# tviic2d6m register map
Vendor: Infineon Technologies; Series: TVIIC2D6M; File version: 1.0
CPU: CM7 r0p1, little endian, MPU, FPU, double-precision FPU, I-cache, D-cache, VTOR, ITCM, DTCM, 3 interrupt priority bits, 16 interrupts
Registers are 32-bit, read-write, reset 0x0 unless marked. A register's access mark holds for its fields unless they carry their own. Offsets are from the block's base; [hi:lo] are bit positions; lines under a group give offsets from that group; {n}, {i} and the like mark numbered series.

## PROT — Protection
Base 0x40230000
0x00 SMPU group
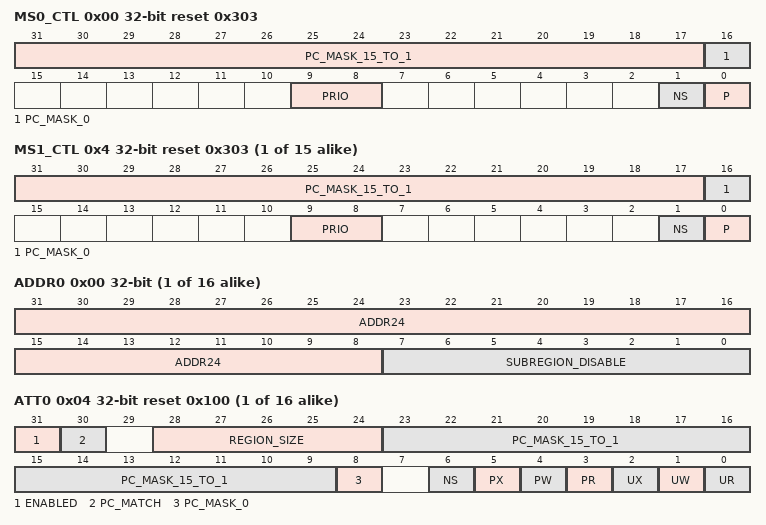
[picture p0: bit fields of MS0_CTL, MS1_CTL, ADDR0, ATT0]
  0x00 MS0_CTL reset 0x303 — Master 0 protection context control
    [31:17] PC_MASK_15_TO_1 — Protection context mask for protection contexts '15' down to '1'. Bit PC_MASK_15_TO_1[i] indicates if the MPU MS_CTL.PC[3:0] protection context field can be set to the value 'i+1': - PC_MASK_15_TO_1[i] is '0': MPU MS_CTL.PC[3:0] can NOT be set to 'i+1'; and PC[3:0] is not changed. If the protection context of the write transfer is '0', protection is not applied and PC[3:0] can be changed. - PC_MASK_15_TO_1[i] is '1': MPU MS_CTL.PC[3:0] can be set to 'i+1'. Note: When CPUSS_CM0_PC_CTL.VALID[i] is '1' (the associated protection context handler is valid), write transfers to PC_MASK_15_TO_1[i-1] always write '0', regardless of data written. This ensures that when valid protection context handlers are used to enter protection contexts 1, 2 or 3 through (HW modifies MPU MS_CTL.PC[3:0] on entry of the handler), it is NOT possible for SW to enter those protection contexts (SW modifies MPU MS_CTL.PC[3:0]).
    [16] PC_MASK_0 ro — Protection context mask for protection context '0'. This field is a constant '0': - PC_MASK_0 is '0': MPU MS_CTL.PC[3:0] can NOT be set to '0' and PC[3:0] is not changed. If the protection context of the write transfer is '0', protection is not applied and PC[3:0] can be changed.
    [9:8] PRIO — Device wide bus arbitration priority setting ('0': highest priority, '3': lowest priority). Notes: The AHB-Lite interconnect performs arbitration on the individual beats/transfers of a burst (this optimizes latency over locality/bandwidth). The AXI-Lite interconnects performs a single arbitration for the complete burst (this optimizes locality/bandwidth over latency). Masters with the same priority setting form a 'priority group'. Within a 'priority group', round robin arbitration is performed.
    [1] NS — Security setting ('0': secure mode; '1': non-secure mode). Notes: This field is ONLY used for masters that do NOT provide their own secure/non-secure access control attribute. Note that the default/reset field value provides non-secure mode access capabilities to all masters.
    [0] P — Privileged setting ('0': user mode; '1': privileged mode). Notes: This field is ONLY used for masters that do NOT provide their own user/privileged access control attribute. The default/reset field value provides privileged mode access capabilities.
  {0x0+4j} MS{j}_CTL reset 0x303 (j=1..15) — Master {j} protection context control
    [31:17] PC_MASK_15_TO_1 — See MS0_CTL.PC_MASK_15_TO_1.
    [16] PC_MASK_0 ro — See MS0_CTL.PC_MASK_0.
    [9:8] PRIO — See MS0_CTL.PRIO
    [1] NS — See MS0_CTL.NS.
    [0] P — See MS0_CTL.P.
  {0x2000+0x40*j} SMPU_STRUCT[{j}] (j=0..15) group — SMPU structure
    0x00 ADDR0 reset not defined — SMPU region address 0 (slave structure)
      [31:8] ADDR24 — This field specifies the most significant bits of the 32-bit address of an address region. The region size is defined by ATT0.REGION_SIZE. A region of n Byte is always n Byte aligned. As a result, some of the lesser significant address bits of ADDR24 may be ignored in determining whether a bus transfer address is within an address region. E.g., a 64 KByte address region (REGION_SIZE is '15') is 64 KByte aligned, and ADDR24[7:0] are ignored.
      [7:0] SUBREGION_DISABLE — This field is used to individually disabled the eight equally sized subregions in which a region is partitioned. Subregion disable: Bit 0: subregion 0 disable. Bit 1: subregion 1 disable. Bit 2: subregion 2 disable. Bit 3: subregion 3 disable. Bit 4: subregion 4 disable. Bit 5: subregion 5 disable. Bit 6: subregion 6 disable. Bit 7: subregion 7 disable. E.g., a 64 KByte address region (ATT0.REGION_SIZE is '15') has eight 8 KByte subregions. The access control as defined by ATT0 applies if the bus transfer address is within the address region AND the addressed subregion is NOT disabled. Note that the smallest region size is 256 B and the smallest subregion size is 32 B.
    0x04 ATT0 reset 0x100 (reset mask 0x80000100) — SMPU region attributes 0 (slave structure)
      [31] ENABLED — Region enable: '0': Disabled. A disabled region will never result in a match on the bus transfer address. '1': Enabled. Note: a disabled address region performs logic gating to reduce dynamic power consumption.
      [30] PC_MATCH — This field specifies if the PC field participates in the 'matching' process or the 'access evaluation' process: '0': PC field participates in 'access evaluation'. '1': PC field participates in 'matching'. 'Matching' process. For each protection structure, the process identifies if a transfer address is contained within the address range. This identifies the 'matching' regions. 'Access evaluation' process. For each protection structure, the process evaluates the bus transfer access attributes against the access control attributes. Note that it is possible to define different access control for multiple protection contexts by using multiple protection structures with the same address region and PC_MATCH set to '1'.
      [28:24] REGION_SIZE — This field specifies the region size: '0'-'6': Undefined. '7': 256 B region '8': 512 B region '9': 1 KB region '10': 2 KB region '11': 4 KB region '12': 8 KB region '13': 16 KB region '14': 32 KB region '15': 64 KB region '16': 128 KB region '17': 256 KB region '18': 512 KB region '19': 1 MB region '20': 2 MB region '21': 4 MB region '22': 8 MB region '23': 16 MB region '24': 32 MB region '25': 64 MB region '26': 128 MB region '27': 256 MB region '28': 512 MB region '39': 1 GB region '30': 2 GB region '31': 4 GB region
      [23:9] PC_MASK_15_TO_1 — This field specifies protection context identifier based access control. Bit i: protection context i+1 enable. If '0', protection context i+1 access is disabled; i.e. not allowed. If '1', protection context i+1 access is enabled; i.e. allowed.
      [8] PC_MASK_0 ro — This field specifies protection context identifier based access control for protection context '0'.
      [6] NS — Non-secure: '0': Secure (secure accesses allowed, non-secure access NOT allowed). '1': Non-secure (both secure and non-secure accesses allowed).
      [5] PX — Privileged execute enable: '0': Disabled (privileged, execute accesses are NOT allowed). '1': Enabled (privileged, execute accesses are allowed).
      [4] PW — Privileged write enable: '0': Disabled (privileged, write accesses are NOT allowed). '1': Enabled (privileged, write accesses are allowed).
      [3] PR — Privileged read enable: '0': Disabled (privileged, read accesses are NOT allowed). '1': Enabled (privileged, read accesses are allowed).
      [2] UX — User execute enable: '0': Disabled (user, execute accesses are NOT allowed). '1': Enabled (user, execute accesses are allowed).
      [1] UW — User write enable: '0': Disabled (user, write accesses are NOT allowed). '1': Enabled (user, write accesses are allowed).
      [0] UR — User read enable: '0': Disabled (user, read accesses are NOT allowed). '1': Enabled (user, read accesses are allowed).
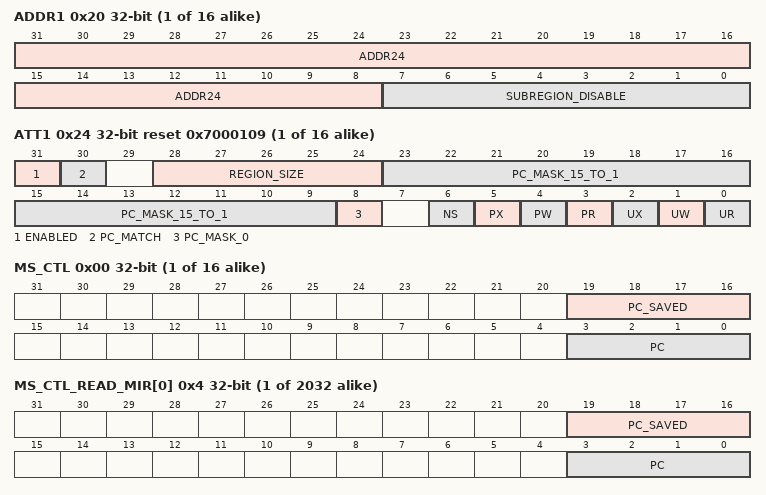
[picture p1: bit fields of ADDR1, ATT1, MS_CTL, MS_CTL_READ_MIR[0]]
    0x20 ADDR1 ro — SMPU region address 1 (master structure)
      [31:8] ADDR24 — This field specifies the most significant bits of the 32-bit address of an address region. 'ADDR_DEF1': base address of structure. Note: this field is read-only.
      [7:0] SUBREGION_DISABLE — This field is used to individually disabled the eight equally sized subregions in which a region is partitioned. Subregion disable: Bit 0: subregion 0 disable. Bit 1: subregion 1 disable. Bit 2: subregion 2 disable. Bit 3: subregion 3 disable. Bit 4: subregion 4 disable. Bit 5: subregion 5 disable. Bit 6: subregion 6 disable. Bit 7: subregion 7 disable. Two out of a total of eight 32 B subregions are enabled. These subregions includes region structures 0 and 1. Note: this field is read-only.
    0x24 ATT1 reset 0x7000109 (reset mask 0x9F00012D) — SMPU region attributes 1 (master structure)
      [31] ENABLED — Region enable: '0': Disabled. A disabled region will never result in a match on the bus transfer address. '1': Enabled.
      [30] PC_MATCH — This field specifies if the PC field participates in the 'matching' process or the 'access evaluation' process: '0': PC field participates in 'access evaluation'. '1': PC field participates in 'matching'. 'Matching' process. For each protection structure, the process identifies if a transfer address is contained within the address range. This identifies the 'matching' regions. 'Access evaluation' process. For each protection structure, the process evaluates the bus transfer access attributes against the access control attributes. Note that it is possible to define different access control for multiple protection contexts by using multiple protection structures with the same address region and PC_MATCH set to '1'.
      [28:24] REGION_SIZE ro — This field specifies the region size: '7': 256 B region (8 32 B subregions) Note: this field is read-only.
      [23:9] PC_MASK_15_TO_1 — This field specifies protection context identifier based access control. Bit i: protection context i+1 enable. If '0', protection context i+1 access is disabled; i.e. not allowed. If '1', protection context i+1 access is enabled; i.e. allowed.
      [8] PC_MASK_0 ro — This field specifies protection context identifier based access control for protection context '0'.
      [6] NS — Non-secure: '0': Secure (secure accesses allowed, non-secure access NOT allowed). '1': Non-secure (both secure and non-secure accesses allowed).
      [5] PX ro — Privileged execute enable: '0': Disabled (privileged, execute accesses are NOT allowed). '1': Enabled (privileged, execute accesses are allowed). Note that this register is constant '0'; i.e. privileged execute accesses are NEVER allowed.
      [4] PW — Privileged write enable: '0': Disabled (privileged, write accesses are NOT allowed). '1': Enabled (privileged, write accesses are allowed).
      [3] PR ro — Privileged read enable: '0': Disabled (privileged, read accesses are NOT allowed). '1': Enabled (privileged, read accesses are allowed). Note that this register is constant '1'; i.e. privileged read accesses are ALWAYS allowed.
      [2] UX ro — User execute enable: '0': Disabled (user, execute accesses are NOT allowed). '1': Enabled (user, execute accesses are allowed). Note that this register is constant '0'; i.e. user execute accesses are NEVER allowed.
      [1] UW — User write enable: '0': Disabled (user, write accesses are NOT allowed). '1': Enabled (user, write accesses are allowed).
      [0] UR ro — User read enable: '0': Disabled (user, read accesses are NOT allowed). '1': Enabled (user, read accesses are allowed). Note that this register is constant '1'; i.e. user read accesses are ALWAYS allowed.
{0x4000+0x400*i} MPU[{i}] (i=0..15) group
  0x00 MS_CTL — Master control
    [19:16] PC_SAVED — Saved protection context. Modifications to this field are constrained by the associated SMPU MS_CTL.PC_MASK_0 and MS_CTL.PC_MASK_15_TO_1[] fields. Note: this field is ONLY used by the CM0+.
    [3:0] PC — Active protection context (PC). Modifications to this field are constrained by the associated SMPU MS_CTL.PC_MASK_0 and MS_CTL.PC_MASK_15_TO_1[] fields. In addition, a write transfer with protection context '0' can change this field (protection context 0 has unrestricted access). The CM0+ MPU MS_CTL register is special: the PC field is modifiable by BOTH HW and SW (for all other masters, the MPU MS_CTL.PC field is modifiable by SW ONLY. For CM0+ PC field HW modifications, the following holds: * On entry of a CM0_PC0/1/2/3_HANDLER exception/interrupt handler: IF (the new PC is the same as MS_CTL.PC) PC is not affected; PC_SAVED is not affected. ELSE IF (CM0_PC_CTL.VALID[MS_CTL.PC]) An AHB-Lite bus error is generated for the exception handler fetch; PC is not affected; PC_SAVED is not affected. ELSE PC = 'new PC'; PC_SAVED = PC (push operation). * On entry of any other exception/interrupt handler: PC = PC_SAVED; PC_SAVED is not affected (pop operation). Note that the CM0_PC0/1/2/3_HANDLER and CM0_PC_CTL registers are part of repecitve CPUSS MMIO registers. Note: this field is NOT used by the DW controllers, DMA controller, AXI DMA controller, CRYPTO component and VIDEOSS.
  {0x4+4j} MS_CTL_READ_MIR[{j}] (j=0..126) ro — Master control read mirror
    [19:16] PC_SAVED — Read-only mirror of MS_CTL.PC_SAVED
    [3:0] PC — Read-only mirror of MS_CTL.PC
  {0x200+0x20*j} MPU_STRUCT[{j}] (j=0..7) group — MPU structure
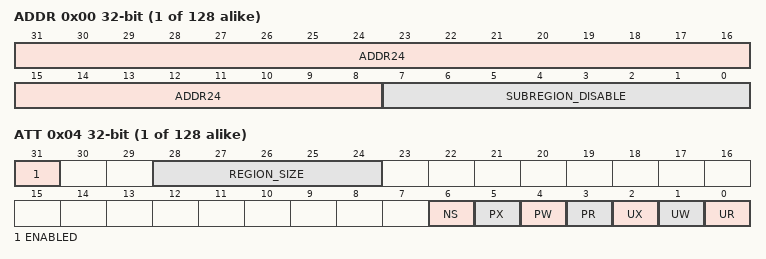
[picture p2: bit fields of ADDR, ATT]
    0x00 ADDR reset not defined — MPU region address
      [31:8] ADDR24 — This field specifies the most significant bits of the 32-bit address of an address region. The region size is defined by ATT.REGION_SIZE. A region of n Byte is always n Byte aligned. As a result, some of the lesser significant address bits of ADDR24 may be ignored in determining whether a bus transfer address is within an address region. E.g., a 64 KByte address region (REGION_SIZE is '15') is 64 KByte aligned, and ADDR24[7:0] are ignored.
      [7:0] SUBREGION_DISABLE — This field is used to individually disabled the eight equally sized subregions in which a region is partitioned. Subregion disable: Bit 0: subregion 0 disable. Bit 1: subregion 1 disable. Bit 2: subregion 2 disable. Bit 3: subregion 3 disable. Bit 4: subregion 4 disable. Bit 5: subregion 5 disable. Bit 6: subregion 6 disable. Bit 7: subregion 7 disable. E.g., a 64 KByte address region (REGION_SIZE is '15') has eight 8 KByte subregions. The access control as defined by MPU_REGION_ATT applies if the bus transfer address is within the address region AND the addressed subregion is NOT disabled. Note that the smallest region size is 256 B and the smallest subregion size is 32 B.
    0x04 ATT (reset mask 0x80000000) — MPU region attrributes
      [31] ENABLED — Region enable: '0': Disabled. A disabled region will never result in a match on the bus transfer address. '1': Enabled. Note: a disabled address region performs logic gating to reduce dynamic power consumption.
      [28:24] REGION_SIZE — This field specifies the region size: '0'-'6': Undefined. '7': 256 B region '8': 512 B region '9': 1 KB region '10': 2 KB region '11': 4 KB region '12': 8 KB region '13': 16 KB region '14': 32 KB region '15': 64 KB region '16': 128 KB region '17': 256 KB region '18': 512 KB region '19': 1 MB region '20': 2 MB region '21': 4 MB region '22': 8 MB region '23': 16 MB region '24': 32 MB region '25': 64 MB region '26': 128 MB region '27': 256 MB region '28': 512 MB region '39': 1 GB region '30': 2 GB region '31': 4 GB region
      [6] NS — Non-secure: '0': Secure (secure accesses allowed, non-secure access NOT allowed). '1': Non-secure (both secure and non-secure accesses allowed).
      [5] PX — Privileged execute enable: '0': Disabled (privileged, execute accesses are NOT allowed). '1': Enabled (privileged, execute accesses are allowed).
      [4] PW — Privileged write enable: '0': Disabled (privileged, write accesses are NOT allowed). '1': Enabled (privileged, write accesses are allowed).
      [3] PR — Privileged read enable: '0': Disabled (privileged, read accesses are NOT allowed). '1': Enabled (privileged, read accesses are allowed).
      [2] UX — User execute enable: '0': Disabled (user, execute accesses are NOT allowed). '1': Enabled (user, execute accesses are allowed).
      [1] UW — User write enable: '0': Disabled (user, write accesses are NOT allowed). '1': Enabled (user, write accesses are allowed).
      [0] UR — User read enable: '0': Disabled (user, read accesses are NOT allowed). '1': Enabled (user, read accesses are allowed).
